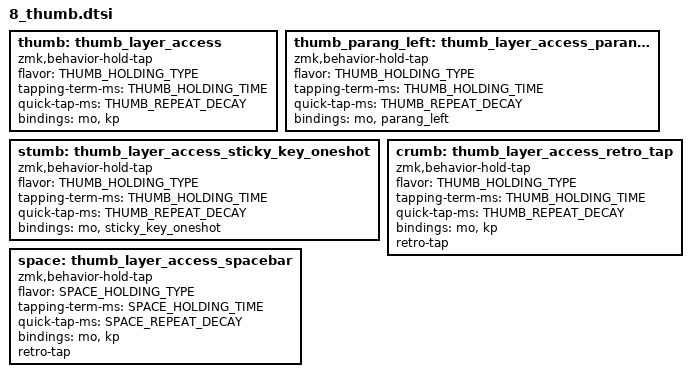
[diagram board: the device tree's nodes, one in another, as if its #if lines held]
  //
  // Thumb cluster hold-tap keys for Miryoku layers
  //
  thumb: thumb_layer_access {
    compatible = "zmk,behavior-hold-tap";
    flavor = THUMB_HOLDING_TYPE;
    tapping-term-ms = <THUMB_HOLDING_TIME>;
    quick-tap-ms = <THUMB_REPEAT_DECAY>; // enable repeat
    #binding-cells = <2>;
    bindings = <&mo>, <&kp>;
  };
  thumb_parang_left: thumb_layer_access_parang_left {
    compatible = "zmk,behavior-hold-tap";
    flavor = THUMB_HOLDING_TYPE;
    tapping-term-ms = <THUMB_HOLDING_TIME>;
    quick-tap-ms = <THUMB_REPEAT_DECAY>; // enable repeat
    #binding-cells = <2>;
    bindings = <&mo>, <&parang_left>;
  };
  stumb: thumb_layer_access_sticky_key_oneshot {
    compatible = "zmk,behavior-hold-tap";
    flavor = THUMB_HOLDING_TYPE;
    tapping-term-ms = <THUMB_HOLDING_TIME>;
    quick-tap-ms = <THUMB_REPEAT_DECAY>; // enable repeat
    #binding-cells = <2>;
    bindings = <&mo>, <&sticky_key_oneshot>;
  };
  crumb: thumb_layer_access_retro_tap {
    compatible = "zmk,behavior-hold-tap";
    flavor = THUMB_HOLDING_TYPE;
    tapping-term-ms = <THUMB_HOLDING_TIME>;
    quick-tap-ms = <THUMB_REPEAT_DECAY>; // enable repeat
    #binding-cells = <2>;
    bindings = <&mo>, <&kp>;
    #ifdef THUMB_FORGIVENESS
    retro-tap;
    #endif
  };
  space: thumb_layer_access_spacebar {
    compatible = "zmk,behavior-hold-tap";
    flavor = SPACE_HOLDING_TYPE;
    tapping-term-ms = <SPACE_HOLDING_TIME>;
    quick-tap-ms = <SPACE_REPEAT_DECAY>; // enable repeat
    #binding-cells = <2>;
    bindings = <&mo>, <&kp>;
    #ifdef SPACE_FORGIVENESS
    retro-tap; // tap on standalone hold
    #endif
  };
